# V32F20x_CM0 register map
File version: 1.0.1
CPU: CM0 r0p0, little endian, no MPU, no FPU, 2 interrupt priority bits
Registers are 32-bit, read-write, reset 0x0 unless marked. A register's access mark holds for its fields unless they carry their own. Offsets are from the block's base; lines under a group give offsets from that group; [hi:lo] are bit positions; {n}, {i} and the like mark numbered series; 'fields as' and 'values as' point back to an identical list; <NAME> marks a mode.

## Memory map
0x21014000 WAVER size 0x1000 — WAVER Peripheral Interface
0x21015000 HFM size 0x1000 — HFM Peripheral Interface
0x21030000 SYSCFG1 size 0x800 — SYSCFG1 Peripheral Interface
0x41010000 I2C14 size 0x800 — I2C14 Peripheral Interface
0x41020000 BSPI0 size 0x800 — BSPI0 Peripheral Interface
0x41020800 BSPI1 size 0x800
0x41021000 BSPI2 size 0x800
0x41021800 BSPI3 size 0x800
0x41022000 BSPI4 size 0x800
0x41022800 BSPI5 size 0x800
0x41030000 UART14 size 0x800 — UART14 Peripheral Interface
0x41030800 UART15 size 0x800
0x41031000 UART16 size 0x800
0x41031800 UART17 size 0x800
0x41032000 UART18 size 0x800
0x41032800 UART19 size 0x800
0x41040000 ISO78162 size 0x40 — ISO78162 Peripheral Interface
0x41040040 ISO78163 size 0x40
0x41050000 BTMR4 size 0x20 — BTMR4 Peripheral Interface
0x41050020 BTMR5 size 0x20
0x41050040 BTMR6 size 0x20
0x41050060 BTMR7 size 0x20
0x41050100 BPWM4 size 0x20 — BPWM4 Peripheral Interface
0x41050120 BPWM5 size 0x20
0x41050140 BPWM6 size 0x20
0x41050160 BPWM7 size 0x20
0x410501F0 BPWMMUX1 size 0x10 — BPWMMUX1 Peripheral Interface
0x41080800 BDMA size 0x800 — BDMA Peripheral Interface
0x41090000 WDT2 size 0x800 — WDT2 Peripheral Interface
0x41100000 RETRAM size 0x800 — RETRAM Peripheral Interface
0x41100800 PMU size 0x800 — PMU Peripheral Interface
0x41101800 COMP size 0x800 — COMP Peripheral Interface
0x41102000 SYSCFGLP size 0x800 — SYSCFGLP Peripheral Interface
0x41102800 RTCALM size 0x800 — RTCALM Peripheral Interface
0x41103000 RTC size 0x800 — RTC Peripheral Interface
0x41103800 RTCANA size 0x800 — RTCANA Peripheral Interface
0x41104000 GPIOA size 0x400 — GPIOA Peripheral Interface
0x41104400 GPIOB size 0x400
0x41104800 GPIOC size 0x400
0x41104C00 GPIOD size 0x400
0x41105000 GPIOE size 0x400
0x41105400 GPIOF size 0x400
0x41105800 GPIOG size 0x400
0x41105C00 GPIOH size 0x400
0x41106000 GPIOI size 0x400
0x41106800 EXTI size 0x800 — EXTI Peripheral Interface
0x41107000 VGIO size 0x400 — VGIO Peripheral Interface
0x41108000 LPBTMR0 size 0x20
0x41109000 LPBTMR1 size 0x20
0x41208000 FLASH0 size 0x4000 — FLASH0 Peripheral Interface
0x4120C000 CRYPT size 0x1000 — CRYPT Peripheral Interface

## Interrupts
0 PMU0 (HFM) — PMU0 interrupt
1 I2C14 (HFM) — I2C14 interrupt
2 BDMA (HFM) — BDMA interrupt
3 UART14 (HFM) — UART14 interrupt
4 UART15 (HFM) — UART15 interrupt
5 UART16 (HFM) — UART16 interrupt
6 UART17 (HFM) — UART17 interrupt
7 UART18 (HFM) — UART18 interrupt
8 UART19 (HFM) — UART19 interrupt
9 ISO78162_3 (HFM) — ISO78162_3 interrupt
10 RSV10 (HFM) — RSV10 interrupt
11 MEM0_ECC (HFM) — MEM0_ECC interrupt
12 BTMR4_5 (HFM) — BTMR4_5 interrupt
13 BTMR6 (HFM) — BTMR6 interrupt
14 BTMR7 (HFM) — BTMR7 interrupt
15 BPWM4 (HFM) — BPWM4 interrupt
16 BPWM5 (HFM) — BPWM5 interrupt
17 BPWM6 (HFM) — BPWM6 interrupt
18 BPWM7 (HFM) — BPWM7 interrupt
19 HFM — HFM interrupt
20 BSPI0 (SYSCFG1) — BSPI0 interrupt
21 BSPI_1 (SYSCFG1) — BSPI_1 interrupt
22 BSPI_2 (SYSCFG1) — BSPI_2 interrupt
23 BSPI_3 (SYSCFG1) — BSPI_3 interrupt
24 BSPI_4 (SYSCFG1) — BSPI_4 interrupt
25 BSPI_5 (SYSCFG1) — BSPI_5 interrupt
26 FLASH0 (SYSCFG1) — FLASH0 interrupt
27 RTCALM (SYSCFG1) — RTCALM interrupt
28 MAILBOX0 (SYSCFG1) — MAILBOX0 interrupt
29 GPIO0 (SYSCFG1) — GPIO0 interrupt
30 SYSCFGLP_ANA_CMP (SYSCFG1) — SYSCFGLP_ANA_CMP interrupt
31 LP_BTMR (SYSCFG1) — LP_BTMR interrupt

## WAVER — WAVER Peripheral Interface
Base 0x21014000
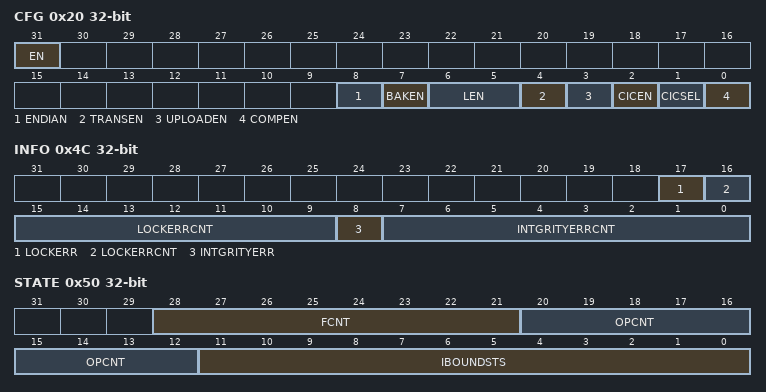
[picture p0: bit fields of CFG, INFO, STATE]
0x20 CFG — WAVER configuration register
  [31] EN — WAVER module enable control.
  [8] ENDIAN — Endian configuration.
  [7] BAKEN — The backup waveform for CM0 processing control.
  [6:5] LEN — The number of samples per-cycle.
  [4] TRANSEN — Transport the upload Waveform to CM33 system enable control
  [3] UPLOADEN — Waveform sample upload enable control.
  [2] CICEN — CIC Down sample enable.
  [1] CICSEL — Down sample rate selection.
  [0] COMPEN — Compensation enable control.
0x30 MODE — WAVER mode configuration register
  [1:0] MODE — Waver mode configuration.
0x40 DATA — WAVER data register
  [31:0] DATA — Sample data buffer candidate for FFT analysis.
0x4C INFO — WAVER information register
  [17] LOCKERR — A Lock Error has been occur between two cycles wave
  [16:9] LOCKERRCNT — Flame count of Lock Error cycles.
  [8] INTGRITYERR — An integrity error occurred while receiving data.
  [7:0] INTGRITYERRCNT — Flame count of Integrity Error cycles.
0x50 STATE — WAVER state register
  [28:21] FCNT — Current flame count.
  [20:12] OPCNT — Current operation count (max 256).
  [11:0] IBOUNDSTS — Integrity Error occur on IB SPI0 interface.
